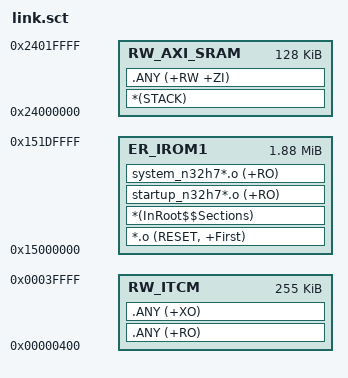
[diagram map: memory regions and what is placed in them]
; *************************************************************
; *** Scatter-Loading Description File generated by uVision ***
; *************************************************************

LR_IROM1 0x15000000 0x001E0000  {    ; load region size_region
  ER_IROM1 0x15000000 0x001E0000  {  ; load address = execution address
   *.o (RESET, +First)
   *(InRoot$$Sections)
   startup_n32h7*.o (+RO)
   system_n32h7*.o (+RO)
  }
  
  ;ITCM 
  RW_ITCM 0x00000400 0x0003FC00  {  ;256K ITCM   offset 0x400 for VECTOR TABLE
   .ANY (+RO)
   .ANY (+XO)
  }
  
  ;AXI SRAM 
  RW_AXI_SRAM 0x24000000 0x00020000  {  ; 128K AXI-SRAM  stack
   *(STACK)
   .ANY (+RW +ZI) 
  }
}

